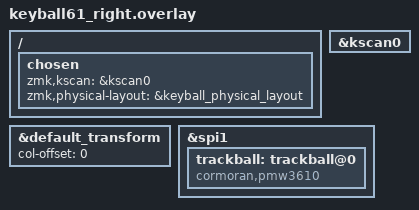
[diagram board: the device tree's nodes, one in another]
/*
 * Copyright (c) 2020 ZMK Contributors
 *
 * SPDX-License-Identifier: MIT
 */

// 1. ベースとなる物理レイアウトの定義ファイルを【必ずインクルードして残し】ます
#include "keyball61.dtsi"

/ {
    chosen {
        // 右手の物理スキャン回路をダイレクトに直結
        zmk,kscan = &kscan0;

        // dtsi内に定義されているZMK Studio用の物理レイアウト構造を正確に指定
        zmk,physical-layout = &keyball_physical_layout;

        // 【最重要】ZMK Studio対応ビルドの安全ロック（BUILD_ASSERT）を解除する命令
        /delete-property/ zmk,matrix-transform;
    };
};

&default_transform {
    // 2. 【最重要】列の「7列ずらし」を完全にゼロに戻すことで、キーの行ズレを100%解消します
    col-offset = <0>;
};

&kscan0 {
    // 3. 右手側の物理スキャン回路を直接フルパワーで走査させ、死んでいた左3列・親指を全て目覚めさせます
    status = "okay";
};

&spi1 {
    trackball: trackball@0 {
        status = "okay";
        // 最新のDYA線環境（Cormoranドライバ）のトラックボール名に適合させます
        compatible = "cormoran,pmw3610"; 
    };
};
